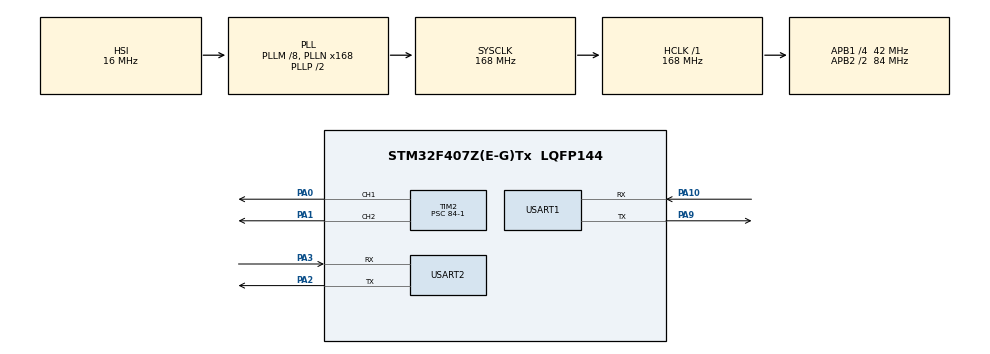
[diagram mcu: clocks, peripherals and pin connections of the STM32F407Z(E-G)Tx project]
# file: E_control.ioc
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Mcu.Family=STM32F4
Mcu.Name=STM32F407Z(E-G)Tx
Mcu.Package=LQFP144
NVIC.PriorityGroup=NVIC_PRIORITYGROUP_4
NVIC.TIM6_DAC_IRQn=true\:15\:0\:false\:false\:true\:false\:true\:true
NVIC.TIM7_IRQn=true\:0\:0\:false\:false\:true\:true\:true\:true
NVIC.TimeBase=TIM6_DAC_IRQn
NVIC.TimeBaseIP=TIM6
NVIC.USART1_IRQn=true\:0\:0\:false\:false\:true\:true\:true\:true
PA0-WKUP.Signal=S_TIM2_CH1_ETR
PA1.Signal=S_TIM2_CH2
PA10.Mode=Asynchronous
PA10.Signal=USART1_RX
PA13.Mode=Serial_Wire
PA13.Signal=SYS_JTMS-SWDIO
PA14.Mode=Serial_Wire
PA14.Signal=SYS_JTCK-SWCLK
PA2.Mode=Asynchronous
PA2.Signal=USART2_TX
PA3.Mode=Asynchronous
PA3.Signal=USART2_RX
PA9.Mode=Asynchronous
PA9.Signal=USART1_TX
PH0-OSC_IN.Mode=HSE-External-Oscillator
PH0-OSC_IN.Signal=RCC_OSC_IN
PH1-OSC_OUT.Mode=HSE-External-Oscillator
PH1-OSC_OUT.Signal=RCC_OSC_OUT
ProjectManager.HeapSize=0x200
ProjectManager.StackSize=0x400
ProjectManager.TargetToolchain=MDK-ARM V5.32
RCC.48MHZClocksFreq_Value=84000000
RCC.AHBFreq_Value=168000000
RCC.APB1CLKDivider=RCC_HCLK_DIV4
RCC.APB1Freq_Value=42000000
RCC.APB1TimFreq_Value=84000000
RCC.APB2CLKDivider=RCC_HCLK_DIV2
RCC.APB2Freq_Value=84000000
RCC.APB2TimFreq_Value=168000000
RCC.CortexFreq_Value=168000000
RCC.HCLKFreq_Value=168000000
RCC.HSE_VALUE=25000000
RCC.HSI_VALUE=16000000
RCC.LSE_VALUE=32768
RCC.PLLM=8
RCC.PLLN=168
RCC.SYSCLKFreq_VALUE=168000000
RCC.SYSCLKSource=RCC_SYSCLKSOURCE_PLLCLK
RCC.VCOOutputFreq_Value=336000000
SH.S_TIM2_CH1_ETR.0=TIM2_CH1,PWM Generation1 CH1
SH.S_TIM2_CH2.0=TIM2_CH2,PWM Generation2 CH2
TIM2.Channel-PWM\ Generation1\ CH1=TIM_CHANNEL_1
TIM2.Channel-PWM\ Generation2\ CH2=TIM_CHANNEL_2
TIM2.Period=20000-1
TIM2.Prescaler=84-1
TIM7.Period=10000-1
TIM7.Prescaler=840-1
USART1.VirtualMode=VM_ASYNC
USART2.VirtualMode=VM_ASYNC
VP_SYS_VS_tim6.Mode=TIM6
VP_TIM2_VS_ClockSourceINT.Mode=Internal
VP_TIM7_VS_ClockSourceINT.Mode=Enable_Timer
board=custom

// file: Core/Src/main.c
/* USER CODE BEGIN Header */
/**
  ******************************************************************************
  * @file           : main.c
  * @brief          : Main program body
  ******************************************************************************
  * @attention
  *
  * Copyright (c) 2024 STMicroelectronics.
  * All rights reserved.
  *
  * This software is licensed under terms that can be found in the LICENSE file
  * in the root directory of this software component.
  * If no LICENSE file comes with this software, it is provided AS-IS.
  *
  ******************************************************************************
  */
/* USER CODE END Header */
#include "main.h"
#include "tim.h"
#include "usart.h"
#include "gpio.h"

/* USER CODE BEGIN PTD */
uint8_t cmd;uint8_t cmd2;
uint8_t send;
/* USER CODE END PTD */

void SystemClock_Config(void);

int main(void)
{

  /* MCU Configuration--------------------------------------------------------*/

  /* Reset of all peripherals, Initializes the Flash interface and the Systick. */
  HAL_Init();

  /* Configure the system clock */
  SystemClock_Config();

  /* Initialize all configured peripherals */
  MX_GPIO_Init();
  MX_TIM2_Init();
  MX_TIM7_Init();
  MX_USART1_UART_Init();
  MX_USART2_UART_Init();
  /* USER CODE BEGIN 2 */
  HAL_TIM_PWM_Start(&htim2,TIM_CHANNEL_1);
  HAL_TIM_PWM_Start(&htim2,TIM_CHANNEL_1);
  HAL_TIM_Base_Start_IT(&htim7);
  HAL_UART_Transmit(&huart1,&send,1,1);
  HAL_UART_Receive_IT(&huart1,(uint8_t *)&cmd,1);
  /* USER CODE END 2 */

  /* Infinite loop */
  /* USER CODE BEGIN WHILE */
  while (1)
  {

    HAL_UART_Receive(&huart2,(uint8_t *)&cmd2,1,1);
    if(cmd2 == 1)printf("%d",cmd2);
    /* USER CODE END WHILE */

  }
}

void SystemClock_Config(void)
{
  RCC_OscInitTypeDef RCC_OscInitStruct = {0};
  RCC_ClkInitTypeDef RCC_ClkInitStruct = {0};

  /** Configure the main internal regulator output voltage
  */
  __HAL_RCC_PWR_CLK_ENABLE();
  __HAL_PWR_VOLTAGESCALING_CONFIG(PWR_REGULATOR_VOLTAGE_SCALE1);

  /** Initializes the RCC Oscillators according to the specified parameters
  * in the RCC_OscInitTypeDef structure.
  */
  RCC_OscInitStruct.OscillatorType = RCC_OSCILLATORTYPE_HSI;
  RCC_OscInitStruct.HSIState = RCC_HSI_ON;
  RCC_OscInitStruct.HSICalibrationValue = RCC_HSICALIBRATION_DEFAULT;
  RCC_OscInitStruct.PLL.PLLState = RCC_PLL_ON;
  RCC_OscInitStruct.PLL.PLLSource = RCC_PLLSOURCE_HSI;
  RCC_OscInitStruct.PLL.PLLM = 8;
  RCC_OscInitStruct.PLL.PLLN = 168;
  RCC_OscInitStruct.PLL.PLLP = RCC_PLLP_DIV2;
  RCC_OscInitStruct.PLL.PLLQ = 4;
  if (HAL_RCC_OscConfig(&RCC_OscInitStruct) != HAL_OK)
  {
    Error_Handler();
  }

  /** Initializes the CPU, AHB and APB buses clocks
  */
  RCC_ClkInitStruct.ClockType = RCC_CLOCKTYPE_HCLK|RCC_CLOCKTYPE_SYSCLK
                              |RCC_CLOCKTYPE_PCLK1|RCC_CLOCKTYPE_PCLK2;
  RCC_ClkInitStruct.SYSCLKSource = RCC_SYSCLKSOURCE_PLLCLK;
  RCC_ClkInitStruct.AHBCLKDivider = RCC_SYSCLK_DIV1;
  RCC_ClkInitStruct.APB1CLKDivider = RCC_HCLK_DIV4;
  RCC_ClkInitStruct.APB2CLKDivider = RCC_HCLK_DIV2;

  if (HAL_RCC_ClockConfig(&RCC_ClkInitStruct, FLASH_LATENCY_5) != HAL_OK)
  {
    Error_Handler();
  }
}

/* USER CODE BEGIN 4 */
void HAL_UART_RxCpltCallback(UART_HandleTypeDef *huart)
{
  if(huart == &huart1)
  {
    COM_Receive_SERVO(cmd);
  }

}

/* USER CODE END 4 */

void HAL_TIM_PeriodElapsedCallback(TIM_HandleTypeDef *htim)
{
  /* USER CODE BEGIN Callback 0 */
  if (htim->Instance == TIM7) {
  }
  /* USER CODE END Callback 0 */
  if (htim->Instance == TIM6) {
    HAL_IncTick();
  }
}

void Error_Handler(void)
{
  __disable_irq();
  while (1)
  {
  }
}
